AUTOSAR XML (schema 4-2-2)
package /Components
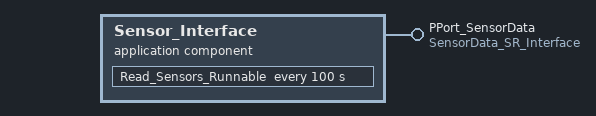
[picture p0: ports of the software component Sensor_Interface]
  application sw component type Sensor_Interface
    provide port PPort_SensorData: provided-interface=SensorData_SR_Interface
    behavior Sensor_Interface_Behavior
      timing event Sensor_Sampling_Event: start-on-event=Read_Sensors_Runnable, period=100
      runnable Read_Sensors_Runnable: minimum-start-interval=100, symbol=Sensor_Interface_Read_Sensors
        data-send-points:
          access RawTemp{1..3}_DataSend: accessed-variable=PPort_SensorData.RawTemp{1..3}
